# AC7842x register map
Vendor: AutoChips; Series: AC78; File version: 1.0
CPU: CM4 r0p1, little endian, MPU, FPU, VTOR, 4 interrupt priority bits
Registers are 32-bit, read-write, reset 0x0 unless marked. A register's access mark holds for its fields unless they carry their own. Offsets are from the block's base; [hi:lo] are bit positions; {n}, {i} and the like mark numbered series.

## ABIST — Analog BIST
Base 0x40005800
0x00 CR — ABIST Control Register
  [2:0] SOFT_START — Software trigger for ABIST
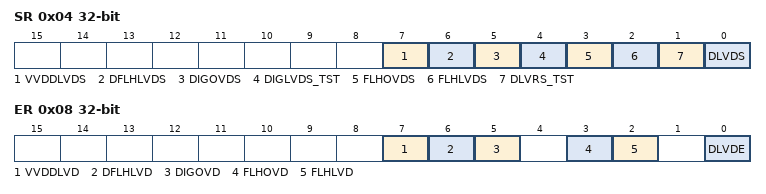
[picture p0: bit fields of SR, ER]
0x04 SR — ABIST Status Register
  [all] fields
    0=fail; 1=Success
  [7] VVDDLVDS — Internal VVDD low voltage detector ABIST result
  [6] DFLHLVDS — DIGLDO to flash low voltage detector ABIST result
  [5] DIGOVDS — DIGLDO over voltage detector ABIST result
  [4] DIGLVDS_TST — Tester for DIGLDO low voltage detector ABIST result
  [3] FLHOVDS — FLHLDO over voltage detector ABIST result
  [2] FLHLVDS — FLHLDO low voltage detector ABIST result
  [1] DLVRS_TST — test for DVDD low voltage Reset ABIST result
  [0] DLVDS — DVDD low voltage detector ABIST result
0x08 ER — LVD or OVD event Register
  [all] fields
    0=no recond; 1=occurred
  [7] VVDDLVD — Internal VVDD low voltage detector warning event flag
  [6] DFLHLVD — DIGLDO to flash low voltage detector warning event flag
  [5] DIGOVD — DIGLDO over voltage detector warning event flag
  [3] FLHOVD — FLHLDO over voltage detector warning event flag
  [2] FLHLVD — FLHLDO low voltage detector warning event flag
  [0] DLVDE — DVDD low voltage detector warning event flag

## PDT0 — Programmable Delay Timer
Base 0x40086000
Same registers: PDT1 0x40086800
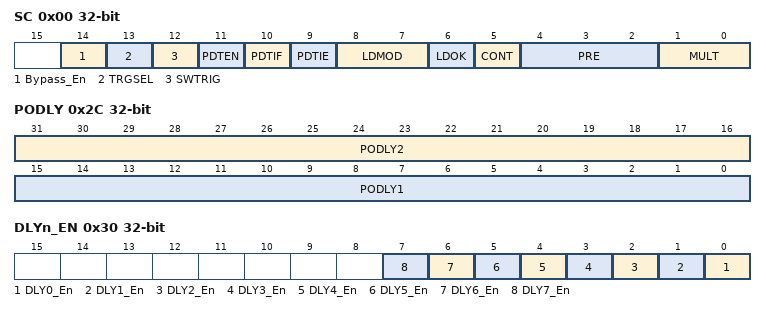
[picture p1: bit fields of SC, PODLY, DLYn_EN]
0x00 SC — PDT Config Register 1
  [14] Bypass_En — Bypass enable
    0=Delay Mode; 1=Bypass of all delay channel,output trigger immediately when receiving a trigger
  [13] TRGSEL — Trigger Input Source Select
    0=Hardware Trigger; 1=Software Trigger
  [12] SWTRIG — Software Trigger
    0=Writing 0 to SWTRIG has no effect; 1=Writing 1 to SWTRIG,Resets and restarts the counter
  [11] PDTEN — PDT Enable
    0=PDT Disable,Counter is Off; 1=PDT Enable
  [10] PDTIF — PDT Interrupt Flag
    0=Write Zero to Clear PDTIF; 1=Writing 1 to PDTIF has no effect
  [9] PDTIE — PDT Interrupt Enable
    0=PDT Interrupt disabled; 1=PDT Interrupt enabled
  [8:7] LDMOD — Load Mode Select
    0=Load After 1 is Written to LDOK; 1=Load When the PDT Counter(CNT) = MODE + 1, After 1 is Written to LDOK; 2=Load When a trigger input event is detected, After 1 is Written to LDOK; 3=Load When the PDT Counter(CNT) = MODE + 1, or a trigger input event is detected, After 1 is Written to LDOK
  [6] LDOK — Load OK
    0=Write 0 To LDOK Has No Effect; 1=Load OK
  [5] CONT — Continuous Mode Enable
    0=PDT operation In One-Shot Mode; 1=PDT operation In Continuous Mode
  [4:2] PRE — Prescaler Divider Select
    0=Counting uses the peripheral clock divided by MULT; 1=Counting uses the peripheral clock divided by 2 * MULT; 2=Counting uses the peripheral clock divided by 4 * MULT; 3=Counting uses the peripheral clock divided by 8 * MULT; 4=Counting uses the peripheral clock divided by 16 * MULT; 5=Counting uses the peripheral clock divided by 32 * MULT; 6=Counting uses the peripheral clock divided by 64 * MULT; 7=Counting uses the peripheral clock divided by 128 * MULT
  [1:0] MULT — Multiplication Factor Select For Prescaler
    0=Multiplication factor is 1; 1=Multiplication factor is 10; 2=Multiplication factor is 20; 3=Multiplication factor is 40
0x04 MOD reset 0xFFFF — PDT Config Register2
  [15:0] MOD — PDT Modulus
{0x8+4i} DLY{i} (i=0..7) — PDT Config Register{i+3}
  [15:0] DLY{i} — PDT Delay{i}
0x28 IDLY reset 0xFFFF — PDT Config Register11
  [15:0] IDLY — PDT Interrupt Delay
0x2C PODLY — PDT Config Register12
  [31:16] PODLY2 — PDT Pulse-Out Delay2
  [15:0] PODLY1 — PDT Pulse-Out Delay1
0x30 DLYn_EN — Delay Enable Register
  [n] DLY{n}_En (n=0..7) — PDT DLY{n} Trigger Enable
    0=PDT DLY{n} Disable; 1=PDT DLY{n} Enable
0x34 POEN — Pulse-Out Enable register
  [0] POEN — PDT Pulse-Out Enable
    0=PDT Pulse-Out disable; 1=PDT Pulse-Out Enable
0x38 CNT — Counter register
  [15:0] CNT ro — PDT Counter
